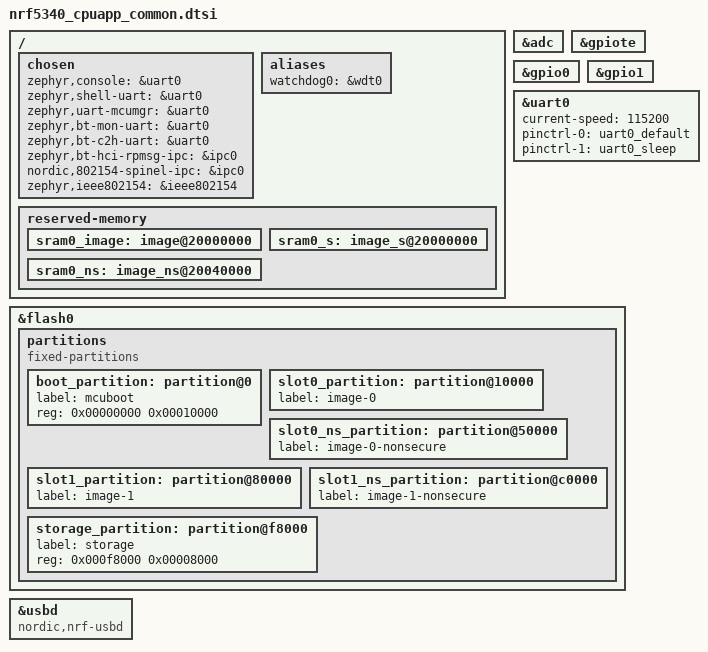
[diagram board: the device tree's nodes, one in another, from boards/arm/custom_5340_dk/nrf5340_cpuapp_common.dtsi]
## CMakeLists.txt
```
# SPDX-License-Identifier: Apache-2.0

cmake_minimum_required(VERSION 3.20.0)

find_package(Zephyr REQUIRED HINTS $ENV{ZEPHYR_BASE})
project(hello_world_1)

target_sources(app PRIVATE src/main.c)
```

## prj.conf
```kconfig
CONFIG_SERIAL=y
CONFIG_UART_INTERRUPT_DRIVEN=n
CONFIG_UART_ASYNC_API=y
```

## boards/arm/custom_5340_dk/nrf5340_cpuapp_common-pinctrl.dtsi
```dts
/*
 * Copyright (c) 2022 Nordic Semiconductor
 * SPDX-License-Identifier: Apache-2.0
 */

&pinctrl {
	uart0_default: uart0_default {
		group1 {
			psels = <NRF_PSEL(UART_TX, 0, 20)>,
				<NRF_PSEL(UART_RTS, 0, 19)>;
		};
		group2 {
			psels = <NRF_PSEL(UART_RX, 0, 22)>,
				<NRF_PSEL(UART_CTS, 0, 21)>;
			bias-pull-up;
		};
	};

	uart0_sleep: uart0_sleep {
		group1 {
			psels = <NRF_PSEL(UART_TX, 0, 20)>,
				<NRF_PSEL(UART_RX, 0, 22)>,
				<NRF_PSEL(UART_RTS, 0, 19)>,
				<NRF_PSEL(UART_CTS, 0, 21)>;
			low-power-enable;
		};
	};

	uart1_default: uart1_default {
		group1 {
			psels = <NRF_PSEL(UART_TX, 1, 1)>;
		};
		group2 {
			psels = <NRF_PSEL(UART_RX, 1, 0)>;
			bias-pull-up;
		};
	};

	uart1_sleep: uart1_sleep {
		group1 {
			psels = <NRF_PSEL(UART_TX, 1, 1)>,
				<NRF_PSEL(UART_RX, 1, 0)>;
			low-power-enable;
		};
	};
};
```

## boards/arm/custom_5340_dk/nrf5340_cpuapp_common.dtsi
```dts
/*
 * Copyright (c) 2019-2020 Nordic Semiconductor ASA
 *
 * SPDX-License-Identifier: Apache-2.0
 */
#include "nrf5340_cpuapp_common-pinctrl.dtsi"
#include <zephyr/dt-bindings/input/input-event-codes.h>

/ {

	chosen {
		zephyr,console = &uart0;
		zephyr,shell-uart = &uart0;
		zephyr,uart-mcumgr = &uart0;
		zephyr,bt-mon-uart = &uart0;
		zephyr,bt-c2h-uart = &uart0;
		zephyr,bt-hci-rpmsg-ipc = &ipc0;
		nordic,802154-spinel-ipc = &ipc0;
		zephyr,ieee802154 = &ieee802154;
	};

	// leds {
	// 	compatible = "gpio-leds";
	// 	led0: led_0 {
	// 		gpios = <&gpio0 28 GPIO_ACTIVE_LOW>;
	// 		label = "Green LED 0";
	// 	};
	// 	led1: led_1 {
	// 		gpios = <&gpio0 29 GPIO_ACTIVE_LOW>;
	// 		label = "Green LED 1";
	// 	};
	// 	led2: led_2 {
	// 		gpios = <&gpio0 30 GPIO_ACTIVE_LOW>;
	// 		label = "Green LED 2";
	// 	};
	// 	led3: led_3 {
	// 		gpios = <&gpio0 31 GPIO_ACTIVE_LOW>;
	// 		label = "Green LED 3";
	// 	};
	// };

	// buttons {
	// 	compatible = "gpio-keys";
	// 	button0: button_0 {
	// 		gpios = <&gpio0 23 (GPIO_PULL_UP | GPIO_ACTIVE_LOW)>;
	// 		label = "Push button 1";
	// 		zephyr,code = <INPUT_KEY_0>;
	// 	};
	// 	button1: button_1 {
	// 		gpios = <&gpio0 24 (GPIO_PULL_UP | GPIO_ACTIVE_LOW)>;
	// 		label = "Push button 2";
	// 		zephyr,code = <INPUT_KEY_1>;
	// 	};
	// 	button2: button_2 {
	// 		gpios = <&gpio0 8 (GPIO_PULL_UP | GPIO_ACTIVE_LOW)>;
	// 		label = "Push button 3";
	// 		zephyr,code = <INPUT_KEY_2>;
	// 	};
	// 	button3: button_3 {
	// 		gpios = <&gpio0 9 (GPIO_PULL_UP | GPIO_ACTIVE_LOW)>;
	// 		label = "Push button 4";
	// 		zephyr,code = <INPUT_KEY_3>;
	// 	};
	// };

	// gpio_fwd: nrf-gpio-forwarder {
	// 	compatible = "nordic,nrf-gpio-forwarder";
	// 	status = "okay";
	// 	uart {
	// 		gpios = <&gpio1 1 0>, <&gpio1 0 0>, <&gpio0 11 0>, <&gpio0 10 0>;
	// 	};


	// 	nrf21540-gpio-if {
	// 		gpios = <&arduino_header 11 0>,		/* tx-en-gpios */
	// 			<&arduino_header 9 0>,		/* rx-en-gpios */
	// 			<&arduino_header 15 0>,		/* pdn-gpios */
	// 			<&arduino_header 10 0>,		/* ant-sel-gpios */
	// 			<&arduino_header 8 0>;		/* mode-gpios */
	// 	};
	// 	nrf21540-spi-if {
	// 		gpios = <&arduino_header 16 0>,		/* cs-gpios */
	// 			<&gpio1 15 0>,			/* SPIM_SCK */
	// 			<&gpio1 14 0>,			/* SPIM_MISO */
	// 			<&gpio1 13 0>;			/* SPIM_MOSI */
	// 	};
	// };

	// nrf_radio_fem: nrf21540_fem {
	// 	compatible = "nordic,nrf21540-fem";
	// 	tx-en-gpios = <&arduino_header 11 GPIO_ACTIVE_HIGH>;   /* D5 */
	// 	rx-en-gpios = <&arduino_header 9 GPIO_ACTIVE_HIGH>;    /* D3 */
	// 	pdn-gpios = <&arduino_header 15 GPIO_ACTIVE_HIGH>;     /* D9 */
	// 	ant-sel-gpios = <&arduino_header 10 GPIO_ACTIVE_HIGH>; /* D4 */
	// 	mode-gpios = <&arduino_header 8 GPIO_ACTIVE_HIGH>;     /* D2 */
	// 	// spi-if = <&nrf_radio_fem_spi>;
	// 	supply-voltage-mv = <3000>;
	// };

	/* These aliases are provided for compatibility with samples */
	aliases {
		// led0 = &led0;
		// led1 = &led1;
		// led2 = &led2;
		// led3 = &led3;
		// sw0 = &button0;
		// sw1 = &button1;
		// sw2 = &button2;
		// sw3 = &button3;
		watchdog0 = &wdt0;
	};
};

&adc {
	status = "okay";
};

&gpiote {
	status = "okay";
};

&gpio0 {
	status = "okay";
};

&gpio1 {
	status = "okay";
};

&uart0 {
	status = "okay";
	current-speed = <115200>;
	pinctrl-0 = <&uart0_default>;
	pinctrl-1 = <&uart0_sleep>;
	pinctrl-names = "default", "sleep";
};

&flash0 {

	partitions {
		compatible = "fixed-partitions";
		#address-cells = <1>;
		#size-cells = <1>;

		boot_partition: partition@0 {
			label = "mcuboot";
			reg = <0x00000000 0x00010000>;
		};
		slot0_partition: partition@10000 {
			label = "image-0";
		};
		slot0_ns_partition: partition@50000 {
			label = "image-0-nonsecure";
		};
		slot1_partition: partition@80000 {
			label = "image-1";
		};
		slot1_ns_partition: partition@c0000 {
			label = "image-1-nonsecure";
		};
		/* 0xf0000 to 0xf7fff reserved for TF-M partitions */
		storage_partition: partition@f8000 {
			label = "storage";
			reg = <0x000f8000 0x00008000>;
		};
	};
};

zephyr_udc0: &usbd {
	compatible = "nordic,nrf-usbd";
	status = "okay";
};

/ {

	reserved-memory {
		#address-cells = <1>;
		#size-cells = <1>;
		ranges;

		sram0_image: image@20000000 {
			/* Zephyr image(s) memory */
		};

		sram0_s: image_s@20000000 {
			/* Secure image memory */
		};

		sram0_ns: image_ns@20040000 {
			/* Non-Secure image memory */
		};
	};
};

/* Include partition configuration file */
#include "nrf5340_cpuapp_partition_conf.dtsi"
```

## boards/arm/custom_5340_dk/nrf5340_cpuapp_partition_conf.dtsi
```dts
/*
 * Copyright (c) 2019-2020 Nordic Semiconductor ASA
 *
 * SPDX-License-Identifier: Apache-2.0
 */

/*
 * Default Flash planning for CUSTOM CPUAPP (Application MCU).
 *
 * Zephyr build for nRF5340 with ARM TrustZone-M support,
 * implies building Secure and Non-Secure Zephyr images.
 *
 * Secure image will be placed, by default, in flash0
 * (or in slot0, if MCUboot is present).
 * Secure image will use sram0 for system memory.
 *
 * Non-Secure image will be placed in slot0_ns, and use
 * sram0_ns for system memory.
 *
 * Note that the Secure image only requires knowledge of
 * the beginning of the Non-Secure image (not its size).
 */

&slot0_partition {
	reg = <0x00010000 0x40000>;
};

&slot0_ns_partition {
	reg = <0x00050000 0x30000>;
};

&slot1_partition {
	reg = <0x00080000 0x40000>;
};

&slot1_ns_partition {
	reg = <0x000c0000 0x30000>;
};

/* Default SRAM planning when building for nRF5340 with
 * ARM TrustZone-M support
 * - Lowest 256 kB SRAM allocated to Secure image (sram0_s)
 * - Middle 192 kB allocated to Non-Secure image (sram0_ns)
 * - Upper 64 kB SRAM allocated as Shared memory (sram0_shared)
 *   (see nrf5340_shared_sram_planning_conf.dtsi)
 */
&sram0_image {
	reg = <0x20000000 DT_SIZE_K(448)>;
};

&sram0_s {
	reg = <0x20000000 0x40000>;
};

&sram0_ns {
	reg = <0x20040000 0x30000>;
};

/* Include shared RAM configuration file */
#include "nrf5340_shared_sram_planning_conf.dtsi"
```

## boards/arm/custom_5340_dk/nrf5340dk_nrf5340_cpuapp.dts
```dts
/*
 * Copyright (c) 2020 Nordic Semiconductor ASA
 *
 * SPDX-License-Identifier: Apache-2.0
 */

/dts-v1/;
#include <nordic/nrf5340_cpuapp_qkaa.dtsi>
#include "nrf5340_cpuapp_common.dtsi"

/ {
	model = "CUSTOM Application";
	compatible = "nordic,custom-cpuapp";

	chosen {
		zephyr,sram = &sram0_image;
		zephyr,flash = &flash0;
		zephyr,code-partition = &slot0_partition;
		zephyr,sram-secure-partition = &sram0_s;
		zephyr,sram-non-secure-partition = &sram0_ns;
	};
};

&uart2 {
	compatible = "nordic,nrf-uarte";
	current-speed = <9600>;
	status = "okay";
	pinctrl-0 = <&uart1_default>;
	pinctrl-1 = <&uart1_sleep>;
	pinctrl-names = "default", "sleep";
};
```

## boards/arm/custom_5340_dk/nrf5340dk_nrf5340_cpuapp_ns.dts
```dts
/*
 * Copyright (c) 2020 Nordic Semiconductor ASA
 *
 * SPDX-License-Identifier: Apache-2.0
 */

/dts-v1/;
#include <nordic/nrf5340_cpuappns_qkaa.dtsi>
#include "nrf5340_cpuapp_common.dtsi"

/ {
	model = "CUSTOM Application";
	compatible = "nordic,custom-cpuapp";

	chosen {
		zephyr,sram = &sram0_ns;
		zephyr,flash = &flash0;
		zephyr,code-partition = &slot0_ns_partition;
	};
};
```

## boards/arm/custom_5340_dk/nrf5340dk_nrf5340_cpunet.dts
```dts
/*
 * Copyright (c) 2020 Nordic Semiconductor ASA
 *
 * SPDX-License-Identifier: Apache-2.0
 */

/dts-v1/;
#include <nordic/nrf5340_cpunet_qkaa.dtsi>
#include "CUSTOM_cpunet-pinctrl.dtsi"
#include <zephyr/dt-bindings/input/input-event-codes.h>

/ {
	model = "CUSTOM Network";
	compatible = "nordic,custom-cpunet";

	chosen {
		zephyr,console = &uart0;
		zephyr,shell-uart = &uart0;
		zephyr,uart-mcumgr = &uart0;
		zephyr,bt-mon-uart = &uart0;
		zephyr,bt-c2h-uart = &uart0;
		zephyr,bt-hci-rpmsg-ipc = &ipc0;
		nordic,802154-spinel-ipc = &ipc0;
		zephyr,sram = &sram1;
		zephyr,flash = &flash1;
		zephyr,code-partition = &slot0_partition;
		zephyr,ieee802154 = &ieee802154;
	};

	// leds {
	// 	compatible = "gpio-leds";
	// 	led0: led_0 {
	// 		gpios = <&gpio0 28 GPIO_ACTIVE_LOW>;
	// 		label = "Green LED 0";
	// 	};
	// 	led1: led_1 {
	// 		gpios = <&gpio0 29 GPIO_ACTIVE_LOW>;
	// 		label = "Green LED 1";
	// 	};
	// 	led2: led_2 {
	// 		gpios = <&gpio0 30 GPIO_ACTIVE_LOW>;
	// 		label = "Green LED 2";
	// 	};
	// 	led3: led_3 {
	// 		gpios = <&gpio0 31 GPIO_ACTIVE_LOW>;
	// 		label = "Green LED 3";
	// 	};
	// };

	// buttons {
	// 	compatible = "gpio-keys";
	// 	button0: button_0 {
	// 		gpios = <&gpio0 23 (GPIO_PULL_UP | GPIO_ACTIVE_LOW)>;
	// 		label = "Push button 1";
	// 		zephyr,code = <INPUT_KEY_0>;
	// 	};
	// 	button1: button_1 {
	// 		gpios = <&gpio0 24 (GPIO_PULL_UP | GPIO_ACTIVE_LOW)>;
	// 		label = "Push button 2";
	// 		zephyr,code = <INPUT_KEY_1>;
	// 	};
	// 	button2: button_2 {
	// 		gpios = <&gpio0 8 (GPIO_PULL_UP | GPIO_ACTIVE_LOW)>;
	// 		label = "Push button 3";
	// 		zephyr,code = <INPUT_KEY_2>;
	// 	};
	// 	button3: button_3 {
	// 		gpios = <&gpio0 9 (GPIO_PULL_UP | GPIO_ACTIVE_LOW)>;
	// 		label = "Push button 4";
	// 		zephyr,code = <INPUT_KEY_3>;
	// 	};
	// };

	/* These aliases are provided for compatibility with samples */
	aliases {
		// led0 = &led0;
		// led1 = &led1;
		// led2 = &led2;
		// led3 = &led3;
		// sw0 = &button0;
		// sw1 = &button1;
		// sw2 = &button2;
		// sw3 = &button3;
		watchdog0 = &wdt0;
	};
};

// &radio {
//     fem = <&nrf_radio_fem>;
// };

&gpiote {
	status = "okay";
};

&gpio0 {
	status = "okay";
};

&gpio1 {
	status = "okay";
};

&uart0 {
	status = "okay";
	current-speed = <115200>;
	pinctrl-0 = <&uart0_default>;
	pinctrl-1 = <&uart0_sleep>;
	pinctrl-names = "default", "sleep";
};

&flash1 {

	partitions {
		compatible = "fixed-partitions";
		#address-cells = <1>;
		#size-cells = <1>;

		boot_partition: partition@0 {
			label = "mcuboot";
			reg = <0x00000000 0xc000>;
		};
		slot0_partition: partition@c000 {
			label = "image-0";
			reg = <0x0000C000 0x17000>;
		};
		slot1_partition: partition@23000 {
			label = "image-1";
			reg = <0x00023000 0x17000>;
		};
		storage_partition: partition@3a000 {
			label = "storage";
			reg = <0x0003a000 0x6000>;
		};
	};
};

// &ieee802154 {
// 	status = "okay";
// };

/* Include shared RAM configuration file */
#include "nrf5340_shared_sram_planning_conf.dtsi"
```

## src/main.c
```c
#include <zephyr/device.h>
#include <zephyr/drivers/uart.h>
#include <zephyr/kernel.h>
#define BUFFER_SIZE (1024)  // Buffer size for incoming data

static const struct device *uart1_dev = DEVICE_DT_GET(DT_NODELABEL(uart2));
static uint8_t rx_buffer[BUFFER_SIZE];  // Buffer for received data
static volatile size_t rx_len = 0;      // Received data length

void uart1_callback(const struct device *dev, struct uart_event *evt, void *user_data) {
    switch (evt->type) {
    case UART_RX_RDY:  // Data is ready to be processed
        printk("%s", evt->data.rx.buf);
        break;
    default:
        break;
    }
    uart_rx_enable(uart1_dev, rx_buffer, sizeof(rx_buffer), 100000);
}

void main(void) {
    if (!device_is_ready(uart1_dev)) {
        printk("Device not ready\r\n");
        return;
    }

    printk("uart cb set ret %d\r\n", uart_callback_set(uart1_dev, uart1_callback, NULL));
    printk("uart rx en ret %d\r\n", uart_rx_enable(uart1_dev, rx_buffer, sizeof(rx_buffer), 100000));
}
```
